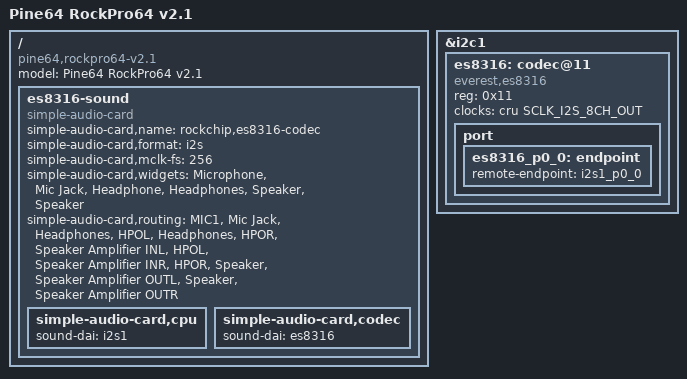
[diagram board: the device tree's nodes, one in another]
// SPDX-License-Identifier: (GPL-2.0+ OR MIT)
/*
 * Copyright (c) 2017 Fuzhou Rockchip Electronics Co., Ltd.
 * Copyright (c) 2018 Akash Gajjar <Akash_Gajjar@mentor.com>
 * Copyright (c) 2019 Katsuhiro Suzuki <katsuhiro@katsuster.net>
 */

/dts-v1/;
#include "rk3399-rockpro64.dtsi"

/ {
	model = "Pine64 RockPro64 v2.1";
	compatible = "pine64,rockpro64-v2.1", "pine64,rockpro64", "rockchip,rk3399";

	/* Audio components */
	es8316-sound {
		compatible = "simple-audio-card";
		pinctrl-names = "default";
		simple-audio-card,name = "rockchip,es8316-codec";
		simple-audio-card,format = "i2s";
		simple-audio-card,mclk-fs = <256>;

		simple-audio-card,widgets =
			"Microphone", "Mic Jack",
			"Headphone", "Headphones",
			"Speaker", "Speaker";
		simple-audio-card,routing =
			"MIC1", "Mic Jack",
			"Headphones", "HPOL",
			"Headphones", "HPOR",
			"Speaker Amplifier INL", "HPOL",
			"Speaker Amplifier INR", "HPOR",
			"Speaker", "Speaker Amplifier OUTL",
			"Speaker", "Speaker Amplifier OUTR";

		simple-audio-card,cpu {
			sound-dai = <&i2s1>;
		};

		simple-audio-card,codec {
			sound-dai = <&es8316>;
		};
	};
};

&i2c1 {
	es8316: codec@11 {
		compatible = "everest,es8316";
		reg = <0x11>;
		clocks = <&cru SCLK_I2S_8CH_OUT>;
		clock-names = "mclk";
		#sound-dai-cells = <0>;

		port {
			es8316_p0_0: endpoint {
				remote-endpoint = <&i2s1_p0_0>;
			};
		};
	};
};
